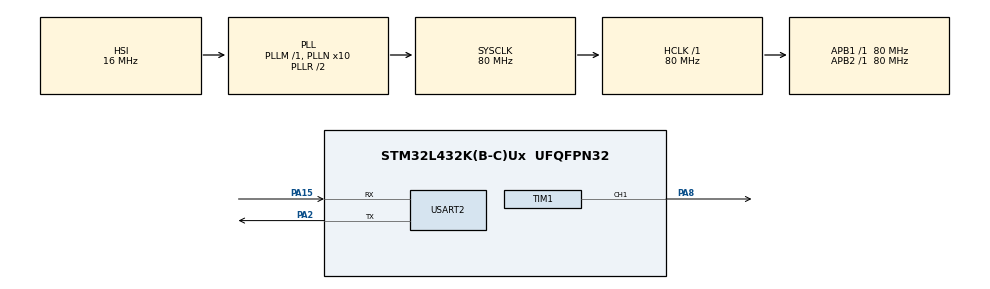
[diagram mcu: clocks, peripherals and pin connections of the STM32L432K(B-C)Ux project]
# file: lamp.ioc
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Dma.Request0=TIM1_CH1
Dma.TIM1_CH1.0.Direction=DMA_MEMORY_TO_PERIPH
Dma.TIM1_CH1.0.Instance=DMA1_Channel2
Dma.TIM1_CH1.0.MemDataAlignment=DMA_MDATAALIGN_BYTE
Dma.TIM1_CH1.0.MemInc=DMA_MINC_ENABLE
Dma.TIM1_CH1.0.Mode=DMA_NORMAL
Dma.TIM1_CH1.0.PeriphDataAlignment=DMA_PDATAALIGN_HALFWORD
Dma.TIM1_CH1.0.PeriphInc=DMA_PINC_DISABLE
Dma.TIM1_CH1.0.Priority=DMA_PRIORITY_LOW
Mcu.Family=STM32L4
Mcu.Name=STM32L432K(B-C)Ux
Mcu.Package=UFQFPN32
NVIC.DMA1_Channel2_IRQn=true\:0\:0\:false\:false\:true\:false\:true\:true
NVIC.PriorityGroup=NVIC_PRIORITYGROUP_4
NVIC.TIM1_BRK_TIM15_IRQn=true\:0\:0\:false\:false\:true\:true\:true\:true
NVIC.TIM1_CC_IRQn=true\:0\:0\:false\:false\:true\:true\:true\:true
NVIC.TIM1_TRG_COM_IRQn=true\:0\:0\:false\:false\:true\:true\:true\:true
NVIC.TIM1_UP_TIM16_IRQn=true\:0\:0\:false\:false\:true\:true\:true\:true
PA0.Mode=HSE-External-Clock-Source-for-LittleOrca
PA0.Signal=RCC_CK_IN
PA13\ (JTMS-SWDIO).Mode=Trace_Asynchronous_SW
PA13\ (JTMS-SWDIO).Signal=SYS_JTMS-SWDIO
PA14\ (JTCK-SWCLK).Mode=Trace_Asynchronous_SW
PA14\ (JTCK-SWCLK).Signal=SYS_JTCK-SWCLK
PA15\ (JTDI).Mode=Asynchronous
PA15\ (JTDI).Signal=USART2_RX
PA2.Mode=Asynchronous
PA2.Signal=USART2_TX
PA8.Signal=S_TIM1_CH1
PB3\ (JTDO-TRACESWO).Mode=Trace_Asynchronous_SW
PB3\ (JTDO-TRACESWO).Signal=SYS_JTDO-SWO
PC14-OSC32_IN\ (PC14).Mode=LSE-External-Oscillator
PC14-OSC32_IN\ (PC14).Signal=RCC_OSC32_IN
PC15-OSC32_OUT\ (PC15).Mode=LSE-External-Oscillator
PC15-OSC32_OUT\ (PC15).Signal=RCC_OSC32_OUT
ProjectManager.HeapSize=0x200
ProjectManager.StackSize=0x400
ProjectManager.TargetToolchain=STM32CubeIDE
RCC.ADCFreq_Value=64000000
RCC.AHBFreq_Value=80000000
RCC.APB1Freq_Value=80000000
RCC.APB1TimFreq_Value=80000000
RCC.APB2Freq_Value=80000000
RCC.APB2TimFreq_Value=80000000
RCC.CortexFreq_Value=80000000
RCC.HCLKFreq_Value=80000000
RCC.HSE_VALUE=8000000
RCC.HSI16_VALUE=16000000
RCC.HSI48_VALUE=48000000
RCC.HSI_VALUE=16000000
RCC.MSI_VALUE=4000000
RCC.PLLMUL=RCC_PLLMUL_4
RCC.PLLN=10
RCC.PLLSourceVirtual=RCC_PLLSOURCE_HSI
RCC.SYSCLKFreq_VALUE=80000000
RCC.SYSCLKSource=RCC_SYSCLKSOURCE_PLLCLK
RCC.USBFreq_Value=64000000
RCC.VCOOutputFreq_Value=160000000
SH.S_TIM1_CH1.0=TIM1_CH1,PWM Generation1 CH1
TIM1.Channel-PWM\ Generation1\ CH1=TIM_CHANNEL_1
TIM1.Period=100-1
TIM1.Prescaler=1-1
USART2.VirtualMode-Asynchronous=VM_ASYNC
board=NUCLEO-L432KC

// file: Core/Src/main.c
/* USER CODE BEGIN Header */
/**
  ******************************************************************************
  * @file           : main.c
  * @brief          : Main program body
  ******************************************************************************
  * @attention
  *
  * Copyright (c) 2024 STMicroelectronics.
  * All rights reserved.
  *
  * This software is licensed under terms that can be found in the LICENSE file
  * in the root directory of this software component.
  * If no LICENSE file comes with this software, it is provided AS-IS.
  *
  ******************************************************************************
  */
/* USER CODE END Header */
#include "main.h"

/* USER CODE BEGIN Includes */
#include "driver_ws2812b.h"
/* USER CODE END Includes */

TIM_HandleTypeDef htim1;
DMA_HandleTypeDef hdma_tim1_ch1;

UART_HandleTypeDef huart2;

void SystemClock_Config(void);
static void MX_GPIO_Init(void);
static void MX_DMA_Init(void);
static void MX_USART2_UART_Init(void);
static void MX_TIM1_Init(void);

/* USER CODE BEGIN 0 */
void HAL_TIM_PWM_PulseFinishedCallback(TIM_HandleTypeDef *htim) {
  ws2812b_callback();
}
/* USER CODE END 0 */

int main(void)
{

  /* MCU Configuration--------------------------------------------------------*/

  /* Reset of all peripherals, Initializes the Flash interface and the Systick. */
  HAL_Init();

  /* Configure the system clock */
  SystemClock_Config();

  /* Initialize all configured peripherals */
  MX_GPIO_Init();
  MX_DMA_Init();
  MX_USART2_UART_Init();
  MX_TIM1_Init();
  /* USER CODE BEGIN 2 */
  ws2812b_init();
  /* USER CODE END 2 */

  /* Infinite loop */
  /* USER CODE BEGIN WHILE */
  while (1)
  {
    for (uint8_t led_i = 0; led_i < LED_COUNT; led_i++) {
      ws2812b_set_colour(led_i, 110, 84, 148);
    }
    ws2812b_update();

    HAL_Delay(500);  // TODO(Daniel): Likely poor practice, schedule?
    /* USER CODE END WHILE */

  }
}

void SystemClock_Config(void)
{
  RCC_OscInitTypeDef RCC_OscInitStruct = {0};
  RCC_ClkInitTypeDef RCC_ClkInitStruct = {0};

  /** Configure the main internal regulator output voltage
  */
  if (HAL_PWREx_ControlVoltageScaling(PWR_REGULATOR_VOLTAGE_SCALE1) != HAL_OK)
  {
    Error_Handler();
  }

  /** Initializes the RCC Oscillators according to the specified parameters
  * in the RCC_OscInitTypeDef structure.
  */
  RCC_OscInitStruct.OscillatorType = RCC_OSCILLATORTYPE_HSI;
  RCC_OscInitStruct.HSIState = RCC_HSI_ON;
  RCC_OscInitStruct.HSICalibrationValue = RCC_HSICALIBRATION_DEFAULT;
  RCC_OscInitStruct.PLL.PLLState = RCC_PLL_ON;
  RCC_OscInitStruct.PLL.PLLSource = RCC_PLLSOURCE_HSI;
  RCC_OscInitStruct.PLL.PLLM = 1;
  RCC_OscInitStruct.PLL.PLLN = 10;
  RCC_OscInitStruct.PLL.PLLP = RCC_PLLP_DIV7;
  RCC_OscInitStruct.PLL.PLLQ = RCC_PLLQ_DIV2;
  RCC_OscInitStruct.PLL.PLLR = RCC_PLLR_DIV2;
  if (HAL_RCC_OscConfig(&RCC_OscInitStruct) != HAL_OK)
  {
    Error_Handler();
  }

  /** Initializes the CPU, AHB and APB buses clocks
  */
  RCC_ClkInitStruct.ClockType = RCC_CLOCKTYPE_HCLK|RCC_CLOCKTYPE_SYSCLK
                              |RCC_CLOCKTYPE_PCLK1|RCC_CLOCKTYPE_PCLK2;
  RCC_ClkInitStruct.SYSCLKSource = RCC_SYSCLKSOURCE_PLLCLK;
  RCC_ClkInitStruct.AHBCLKDivider = RCC_SYSCLK_DIV1;
  RCC_ClkInitStruct.APB1CLKDivider = RCC_HCLK_DIV1;
  RCC_ClkInitStruct.APB2CLKDivider = RCC_HCLK_DIV1;

  if (HAL_RCC_ClockConfig(&RCC_ClkInitStruct, FLASH_LATENCY_4) != HAL_OK)
  {
    Error_Handler();
  }
}

static void MX_TIM1_Init(void)
{

  TIM_MasterConfigTypeDef sMasterConfig = {0};
  TIM_OC_InitTypeDef sConfigOC = {0};
  TIM_BreakDeadTimeConfigTypeDef sBreakDeadTimeConfig = {0};

  htim1.Instance = TIM1;
  htim1.Init.Prescaler = 1-1;
  htim1.Init.CounterMode = TIM_COUNTERMODE_UP;
  htim1.Init.Period = 100-1;
  htim1.Init.ClockDivision = TIM_CLOCKDIVISION_DIV1;
  htim1.Init.RepetitionCounter = 0;
  htim1.Init.AutoReloadPreload = TIM_AUTORELOAD_PRELOAD_DISABLE;
  if (HAL_TIM_PWM_Init(&htim1) != HAL_OK)
  {
    Error_Handler();
  }
  sMasterConfig.MasterOutputTrigger = TIM_TRGO_RESET;
  sMasterConfig.MasterOutputTrigger2 = TIM_TRGO2_RESET;
  sMasterConfig.MasterSlaveMode = TIM_MASTERSLAVEMODE_DISABLE;
  if (HAL_TIMEx_MasterConfigSynchronization(&htim1, &sMasterConfig) != HAL_OK)
  {
    Error_Handler();
  }
  sConfigOC.OCMode = TIM_OCMODE_PWM1;
  sConfigOC.Pulse = 0;
  sConfigOC.OCPolarity = TIM_OCPOLARITY_HIGH;
  sConfigOC.OCNPolarity = TIM_OCNPOLARITY_HIGH;
  sConfigOC.OCFastMode = TIM_OCFAST_DISABLE;
  sConfigOC.OCIdleState = TIM_OCIDLESTATE_RESET;
  sConfigOC.OCNIdleState = TIM_OCNIDLESTATE_RESET;
  if (HAL_TIM_PWM_ConfigChannel(&htim1, &sConfigOC, TIM_CHANNEL_1) != HAL_OK)
  {
    Error_Handler();
  }
  sBreakDeadTimeConfig.OffStateRunMode = TIM_OSSR_DISABLE;
  sBreakDeadTimeConfig.OffStateIDLEMode = TIM_OSSI_DISABLE;
  sBreakDeadTimeConfig.LockLevel = TIM_LOCKLEVEL_OFF;
  sBreakDeadTimeConfig.DeadTime = 0;
  sBreakDeadTimeConfig.BreakState = TIM_BREAK_DISABLE;
  sBreakDeadTimeConfig.BreakPolarity = TIM_BREAKPOLARITY_HIGH;
  sBreakDeadTimeConfig.BreakFilter = 0;
  sBreakDeadTimeConfig.Break2State = TIM_BREAK2_DISABLE;
  sBreakDeadTimeConfig.Break2Polarity = TIM_BREAK2POLARITY_HIGH;
  sBreakDeadTimeConfig.Break2Filter = 0;
  sBreakDeadTimeConfig.AutomaticOutput = TIM_AUTOMATICOUTPUT_DISABLE;
  if (HAL_TIMEx_ConfigBreakDeadTime(&htim1, &sBreakDeadTimeConfig) != HAL_OK)
  {
    Error_Handler();
  }
  HAL_TIM_MspPostInit(&htim1);

}

static void MX_USART2_UART_Init(void)
{

  huart2.Instance = USART2;
  huart2.Init.BaudRate = 115200;
  huart2.Init.WordLength = UART_WORDLENGTH_8B;
  huart2.Init.StopBits = UART_STOPBITS_1;
  huart2.Init.Parity = UART_PARITY_NONE;
  huart2.Init.Mode = UART_MODE_TX_RX;
  huart2.Init.HwFlowCtl = UART_HWCONTROL_NONE;
  huart2.Init.OverSampling = UART_OVERSAMPLING_16;
  huart2.Init.OneBitSampling = UART_ONE_BIT_SAMPLE_DISABLE;
  huart2.AdvancedInit.AdvFeatureInit = UART_ADVFEATURE_NO_INIT;
  if (HAL_UART_Init(&huart2) != HAL_OK)
  {
    Error_Handler();
  }

}

static void MX_DMA_Init(void)
{

  /* DMA controller clock enable */
  __HAL_RCC_DMA1_CLK_ENABLE();

  /* DMA interrupt init */
  /* DMA1_Channel2_IRQn interrupt configuration */
  HAL_NVIC_SetPriority(DMA1_Channel2_IRQn, 0, 0);
  HAL_NVIC_EnableIRQ(DMA1_Channel2_IRQn);

}

static void MX_GPIO_Init(void)
{

  /* GPIO Ports Clock Enable */
  __HAL_RCC_GPIOC_CLK_ENABLE();
  __HAL_RCC_GPIOA_CLK_ENABLE();
  __HAL_RCC_GPIOB_CLK_ENABLE();

}

void Error_Handler(void)
{
  __disable_irq();
  while (1)
  {
  }
}
